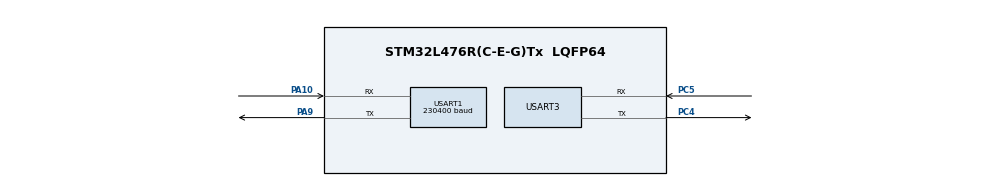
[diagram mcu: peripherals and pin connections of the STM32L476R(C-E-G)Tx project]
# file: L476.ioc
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Dma.Request0=USART1_RX
Dma.Request1=USART1_TX
Dma.USART1_RX.0.Direction=DMA_PERIPH_TO_MEMORY
Dma.USART1_RX.0.Instance=DMA1_Channel5
Dma.USART1_RX.0.MemDataAlignment=DMA_MDATAALIGN_BYTE
Dma.USART1_RX.0.MemInc=DMA_MINC_ENABLE
Dma.USART1_RX.0.Mode=DMA_CIRCULAR
Dma.USART1_RX.0.PeriphDataAlignment=DMA_PDATAALIGN_BYTE
Dma.USART1_RX.0.PeriphInc=DMA_PINC_DISABLE
Dma.USART1_RX.0.Priority=DMA_PRIORITY_LOW
Dma.USART1_TX.1.Direction=DMA_MEMORY_TO_PERIPH
Dma.USART1_TX.1.Instance=DMA1_Channel4
Dma.USART1_TX.1.MemDataAlignment=DMA_MDATAALIGN_BYTE
Dma.USART1_TX.1.MemInc=DMA_MINC_ENABLE
Dma.USART1_TX.1.Mode=DMA_NORMAL
Dma.USART1_TX.1.PeriphDataAlignment=DMA_PDATAALIGN_BYTE
Dma.USART1_TX.1.PeriphInc=DMA_PINC_DISABLE
Dma.USART1_TX.1.Priority=DMA_PRIORITY_LOW
FREERTOS.HEAP_NUMBER=4
FREERTOS.INCLUDE_uxTaskGetStackHighWaterMark=1
FREERTOS.MEMORY_ALLOCATION=2
FREERTOS.Tasks01=defaultTask,0,128,StartDefaultTask,Default,NULL,Static,defaultTaskBuffer,defaultTaskControlBlock
FREERTOS.configTOTAL_HEAP_SIZE=81920
Mcu.Family=STM32L4
Mcu.Name=STM32L476R(C-E-G)Tx
Mcu.Package=LQFP64
NVIC.DMA1_Channel4_IRQn=true\:5\:0\:false\:false\:true\:true\:false\:true
NVIC.DMA1_Channel5_IRQn=true\:5\:0\:false\:false\:true\:true\:false\:true
NVIC.PriorityGroup=NVIC_PRIORITYGROUP_4
NVIC.USART1_IRQn=true\:5\:0\:false\:false\:true\:true\:true\:true
PA10.Mode=Asynchronous
PA10.Signal=USART1_RX
PA13\ (JTMS-SWDIO).Mode=Serial_Wire
PA13\ (JTMS-SWDIO).Signal=SYS_JTMS-SWDIO
PA14\ (JTCK-SWCLK).Mode=Serial_Wire
PA14\ (JTCK-SWCLK).Signal=SYS_JTCK-SWCLK
PA9.Mode=Asynchronous
PA9.Signal=USART1_TX
PC4.Mode=Asynchronous
PC4.Signal=USART3_TX
PC5.Mode=Asynchronous
PC5.Signal=USART3_RX
ProjectManager.HeapSize=0x200
ProjectManager.StackSize=0x400
ProjectManager.TargetToolchain=MDK-ARM V5
RCC.HSE_VALUE=8000000
RCC.HSI_VALUE=16000000
RCC.LSE_VALUE=32768
RCC.MSI_VALUE=4000000
RCC.VCOOutputFreq_Value=32000000
TIM2.AutoReloadPreload=TIM_AUTORELOAD_PRELOAD_ENABLE
TIM2.ClockDivision=TIM_CLOCKDIVISION_DIV1
TIM2.Prescaler=8
USART1.BaudRate=230400
USART1.VirtualMode-Asynchronous=VM_ASYNC
USART3.VirtualMode-Asynchronous=VM_ASYNC
VP_FREERTOS_VS_CMSIS_V1.Mode=CMSIS_V1
VP_TIM2_VS_ClockSourceINT.Mode=Internal
board=custom

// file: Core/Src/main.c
/* USER CODE BEGIN Header */
/**
  ******************************************************************************
  * @file           : main.c
  * @brief          : Main program body
  ******************************************************************************
  * @attention
  *
  * <h2><center>&copy; Copyright (c) 2021 STMicroelectronics.
  * All rights reserved.</center></h2>
  *
  * This software component is licensed by ST under Ultimate Liberty license
  * SLA0044, the "License"; You may not use this file except in compliance with
  * the License. You may obtain a copy of the License at:
  *                             www.st.com/SLA0044
  *
  ******************************************************************************
  */
/* USER CODE END Header */
#include "main.h"
#include "cmsis_os.h"

TIM_HandleTypeDef htim2;

UART_HandleTypeDef huart1;
UART_HandleTypeDef huart3;
DMA_HandleTypeDef hdma_usart1_rx;
DMA_HandleTypeDef hdma_usart1_tx;

osThreadId defaultTaskHandle;
uint32_t defaultTaskBuffer[ 128 ];
osStaticThreadDef_t defaultTaskControlBlock;
void StartDefaultTask(void const * argument);

osThreadId linkkitTaskHandle;
void StartLinkkitTask(void const * argument);

void SystemClock_Config(void);
static void MX_GPIO_Init(void);
static void MX_DMA_Init(void);
static void MX_USART1_UART_Init(void);
static void MX_USART3_UART_Init(void);
static void MX_TIM2_Init(void);

/* USER CODE BEGIN 0 */
/*call linkkit demo*/
extern int link_main(int argc, void *argv[]);

/* USER CODE END 0 */

int main(void)
{

  /* MCU Configuration--------------------------------------------------------*/

  /* Reset of all peripherals, Initializes the Flash interface and the Systick. */
  HAL_Init();

  /* Configure the system clock */
  SystemClock_Config();

  /* Initialize all configured peripherals */
  MX_GPIO_Init();
  MX_DMA_Init();
  MX_USART1_UART_Init();
  MX_USART3_UART_Init();
  MX_TIM2_Init();

  /* Create the thread(s) */
  /* definition and creation of defaultTask */
  osThreadStaticDef(defaultTask, StartDefaultTask, osPriorityNormal, 0, 128, defaultTaskBuffer, &defaultTaskControlBlock);
  defaultTaskHandle = osThreadCreate(osThread(defaultTask), NULL);

  /* USER CODE BEGIN RTOS_THREADS */
	osThreadDef(LinkkitTask, StartLinkkitTask, osPriorityHigh, 0, 1500);
  linkkitTaskHandle = osThreadCreate(osThread(LinkkitTask), NULL);
  /* USER CODE END RTOS_THREADS */

  /* Start scheduler */
  osKernelStart();

  /* We should never get here as control is now taken by the scheduler */
  /* Infinite loop */
  while (1)
  {

  }
}

void SystemClock_Config(void)
{
  RCC_OscInitTypeDef RCC_OscInitStruct = {0};
  RCC_ClkInitTypeDef RCC_ClkInitStruct = {0};
  RCC_PeriphCLKInitTypeDef PeriphClkInit = {0};

  /** Initializes the RCC Oscillators according to the specified parameters
  * in the RCC_OscInitTypeDef structure.
  */
  RCC_OscInitStruct.OscillatorType = RCC_OSCILLATORTYPE_MSI;
  RCC_OscInitStruct.MSIState = RCC_MSI_ON;
  RCC_OscInitStruct.MSICalibrationValue = 0;
  RCC_OscInitStruct.MSIClockRange = RCC_MSIRANGE_6;
  RCC_OscInitStruct.PLL.PLLState = RCC_PLL_NONE;
  if (HAL_RCC_OscConfig(&RCC_OscInitStruct) != HAL_OK)
  {
    Error_Handler();
  }
  /** Initializes the CPU, AHB and APB buses clocks
  */
  RCC_ClkInitStruct.ClockType = RCC_CLOCKTYPE_HCLK|RCC_CLOCKTYPE_SYSCLK
                              |RCC_CLOCKTYPE_PCLK1|RCC_CLOCKTYPE_PCLK2;
  RCC_ClkInitStruct.SYSCLKSource = RCC_SYSCLKSOURCE_MSI;
  RCC_ClkInitStruct.AHBCLKDivider = RCC_SYSCLK_DIV1;
  RCC_ClkInitStruct.APB1CLKDivider = RCC_HCLK_DIV1;
  RCC_ClkInitStruct.APB2CLKDivider = RCC_HCLK_DIV1;

  if (HAL_RCC_ClockConfig(&RCC_ClkInitStruct, FLASH_LATENCY_0) != HAL_OK)
  {
    Error_Handler();
  }
  PeriphClkInit.PeriphClockSelection = RCC_PERIPHCLK_USART1|RCC_PERIPHCLK_USART3;
  PeriphClkInit.Usart1ClockSelection = RCC_USART1CLKSOURCE_PCLK2;
  PeriphClkInit.Usart3ClockSelection = RCC_USART3CLKSOURCE_PCLK1;
  if (HAL_RCCEx_PeriphCLKConfig(&PeriphClkInit) != HAL_OK)
  {
    Error_Handler();
  }
  /** Configure the main internal regulator output voltage
  */
  if (HAL_PWREx_ControlVoltageScaling(PWR_REGULATOR_VOLTAGE_SCALE1) != HAL_OK)
  {
    Error_Handler();
  }
}

static void MX_TIM2_Init(void)
{

  TIM_ClockConfigTypeDef sClockSourceConfig = {0};
  TIM_MasterConfigTypeDef sMasterConfig = {0};

  htim2.Instance = TIM2;
  htim2.Init.Prescaler = 8;
  htim2.Init.CounterMode = TIM_COUNTERMODE_UP;
  htim2.Init.Period = 4294967295;
  htim2.Init.ClockDivision = TIM_CLOCKDIVISION_DIV1;
  htim2.Init.AutoReloadPreload = TIM_AUTORELOAD_PRELOAD_ENABLE;
  if (HAL_TIM_Base_Init(&htim2) != HAL_OK)
  {
    Error_Handler();
  }
  sClockSourceConfig.ClockSource = TIM_CLOCKSOURCE_INTERNAL;
  if (HAL_TIM_ConfigClockSource(&htim2, &sClockSourceConfig) != HAL_OK)
  {
    Error_Handler();
  }
  sMasterConfig.MasterOutputTrigger = TIM_TRGO_RESET;
  sMasterConfig.MasterSlaveMode = TIM_MASTERSLAVEMODE_DISABLE;
  if (HAL_TIMEx_MasterConfigSynchronization(&htim2, &sMasterConfig) != HAL_OK)
  {
    Error_Handler();
  }

}

static void MX_USART1_UART_Init(void)
{

  huart1.Instance = USART1;
  huart1.Init.BaudRate = 115200;
  huart1.Init.WordLength = UART_WORDLENGTH_8B;
  huart1.Init.StopBits = UART_STOPBITS_1;
  huart1.Init.Parity = UART_PARITY_NONE;
  huart1.Init.Mode = UART_MODE_TX_RX;
  huart1.Init.HwFlowCtl = UART_HWCONTROL_NONE;
  huart1.Init.OverSampling = UART_OVERSAMPLING_16;
  huart1.Init.OneBitSampling = UART_ONE_BIT_SAMPLE_DISABLE;
  huart1.AdvancedInit.AdvFeatureInit = UART_ADVFEATURE_NO_INIT;
  if (HAL_UART_Init(&huart1) != HAL_OK)
  {
    Error_Handler();
  }
  /* USER CODE BEGIN USART1_Init 2 */
	__HAL_UART_ENABLE_IT(&huart1, UART_IT_IDLE);
  /* USER CODE END USART1_Init 2 */

}

static void MX_USART3_UART_Init(void)
{

  huart3.Instance = USART3;
  huart3.Init.BaudRate = 115200;
  huart3.Init.WordLength = UART_WORDLENGTH_8B;
  huart3.Init.StopBits = UART_STOPBITS_1;
  huart3.Init.Parity = UART_PARITY_NONE;
  huart3.Init.Mode = UART_MODE_TX_RX;
  huart3.Init.HwFlowCtl = UART_HWCONTROL_NONE;
  huart3.Init.OverSampling = UART_OVERSAMPLING_16;
  huart3.Init.OneBitSampling = UART_ONE_BIT_SAMPLE_DISABLE;
  huart3.AdvancedInit.AdvFeatureInit = UART_ADVFEATURE_NO_INIT;
  if (HAL_UART_Init(&huart3) != HAL_OK)
  {
    Error_Handler();
  }
  /* USER CODE BEGIN USART3_Init 2 */
	//__HAL_UART_ENABLE_IT(&huart3, UART_IT_IDLE);
  /* USER CODE END USART3_Init 2 */

}

static void MX_DMA_Init(void)
{

  /* DMA controller clock enable */
  __HAL_RCC_DMA1_CLK_ENABLE();

  /* DMA interrupt init */
  /* DMA1_Channel4_IRQn interrupt configuration */
  HAL_NVIC_SetPriority(DMA1_Channel4_IRQn, 5, 0);
  HAL_NVIC_EnableIRQ(DMA1_Channel4_IRQn);
  /* DMA1_Channel5_IRQn interrupt configuration */
  HAL_NVIC_SetPriority(DMA1_Channel5_IRQn, 5, 0);
  HAL_NVIC_EnableIRQ(DMA1_Channel5_IRQn);

}

static void MX_GPIO_Init(void)
{

  /* GPIO Ports Clock Enable */
  __HAL_RCC_GPIOC_CLK_ENABLE();
  __HAL_RCC_GPIOA_CLK_ENABLE();

}

void StartDefaultTask(void const * argument)
{
  /* USER CODE BEGIN 5 */
  /* Infinite loop */
  for(;;)
  {
    osDelay(100000);
  }
  /* USER CODE END 5 */
}

void StartLinkkitTask(void const * argument)
{
	link_main(0, NULL);
}

void Error_Handler(void)
{
  __disable_irq();
  while (1)
  {
  }
}

/************************ (C) COPYRIGHT STMicroelectronics *****END OF FILE****/
